# S32R372 register map
Vendor: Freescale Semiconductor, Inc.; Series: Qorivva; File version: 1.6
Registers are 32-bit, read-write, reset 0x0 unless marked. A register's access mark holds for its fields unless they carry their own. Offsets are from the block's base; [hi:lo] are bit positions; {n}, {i} and the like mark numbered series; 'fields as' and 'values as' point back to an identical list.

## CTE — CTE Memory Map
Base 0xFFD0C000; register names take the prefix CTE_
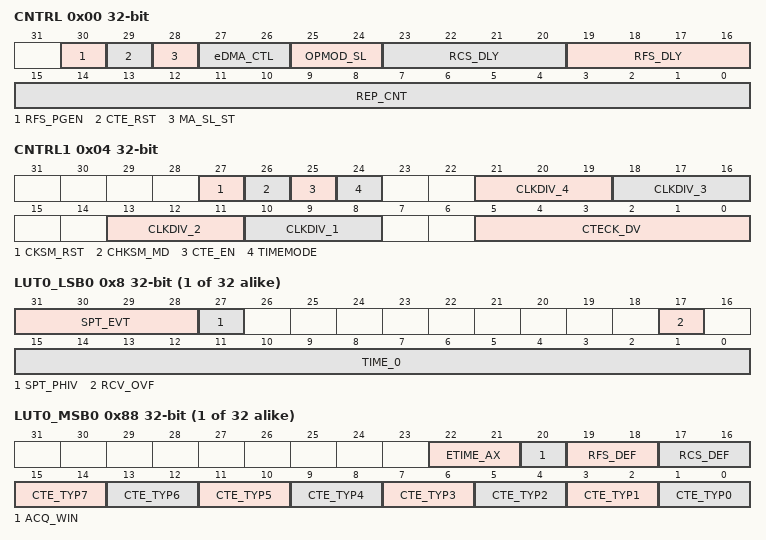
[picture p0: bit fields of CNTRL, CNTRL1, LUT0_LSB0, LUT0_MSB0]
0x00 CNTRL — Control Register
  [30] RFS_PGEN — Internal SW RFS Pulse Trigger. This bit is to be used in Slave mode only.
  [29] CTE_RST — CTE synchronous Reset
    0=CTE module reset is de-asserted; 1=CTE module reset is asserted
  [28] MA_SL_ST — master/slave select
    0=CTE is in master mode (default mode); 1=CTE is in slave mode
  [27:26] eDMA_CTL — eDMA trigger control
    0=eDMA trigger generation disabled; 1=eDMA trigger will be generated at the start of timing table; 2=eDMA trigger will be generated at the end of timing table; 3=Not used. eDMA trigger generation is disabled.
  [25:24] OPMOD_SL — CTE FSM operation mode select.
    0=Halt Mode. In this mode timing generation is stopped.; 2=Continuous run mode, Single table. In this mode the timing table is executed for the number of times programmed in the "lut_rep_cnt".; 3=Continuous toggle mode, 2 tables. In this mode, the timing tables are toggled for the number of times programmed in the "lut_rep_cnt".; 1=Continuous run mode, TT1. In this mode the second timing table (TT1) is executed for the number of times programmed in the "lut_rep_cnt".
  [23:20] RCS_DLY — Radar Chirp Synchronization Delay Control
    0=No Delay; {v}={v} clock cycle delay needs to be introduced (v=1..15)
  [19:16] RFS_DLY — Radar Frame Synchronization Delay Control
    values as RCS_DLY
  [15:0] REP_CNT — Timing Table Repetition Counter
0x04 CNTRL1 — CTE Control Register 1
  [27] CKSM_RST — Checksum Reset
    0=De-asserted. Checksum calculation functions normally.; 1=Checksum calculator block will be held in reset from next cycle onwards
  [26] CHKSM_MD — Checksum Mode
    0=Checksum mode means that the carry on the MSB is dropped (default); 1=MISR mode means that the carry on the MSB is fed back to the LSB of the checksum
  [25] CTE_EN — CTE Enable
    0=CTE is disabled. When this bit is 0, all the pending interrupts, eDMA request will be de-asserted immediately. Operational mode FSM will come to HALT and all the timing signals will be de-asserted. Internal time counter will be reset and the timing table entry counter will point to the 1st location of TT0 and all the interrupt status bits will be cleared.; 1=Timing table execution is enabled. Note that when CTE enable bit is set from 0 to 1 in the middle of operation, the timing table execution will start from address 0.
  [24] TIMEMODE — Time mode type
    0=Relative, internal time counter will reset once it reaches the current timing entry so that the next timing instance becomes relative to the current time instance; 1=Absolute, internal time counter will not be reset hence the signal states are driven at absolute timing instances
  [21:19] CLKDIV_4 — 4th Clock divider
    0=Forth clock divider's frequency is equal to CTE clock frequency; 1=Forth clock divider's frequency is equal to half the CTE clock frequency; 7=Forth clock divider's frequency is equal to 1/128 of CTE clock frequency
  [18:16] CLKDIV_3 — 3rd Clock divider
    0=Third clock divider's frequency is equal to CTE clock frequency; 1=Third clock divider's frequency is equal to half the CTE clock frequency; 7=Third clock divider's frequency is equal to 1/128 of CTE clock frequency
  [13:11] CLKDIV_2 — 2nd Clock divider
    0=Second clock divider's frequency is equal to CTE clock frequency; 1=Second clock divider's frequency is equal to half of the CTE clock frequency; 7=Second clock divider's frequency is equal to 1/128 of CTE clock frequency
  [10:8] CLKDIV_1 — 1st Clock divider
    0=First clock divider's frequency is equal to CTE clock frequency; 1=First clock divider's frequency is equal to half the CTE clock frequency; 7=First clock divider's frequency is equal to 1/128 of the CTE clock frequency
  [5:0] CTECK_DV — CTE Clock divider
    2=Datapath is operating at half the CTE clock frequency; 3=Datapath is operating at 1/3 of CTE clock frequency; 63=Datapath is operating at 1/63 of CTE clock frequency
{0x8+4i} LUT0_LSB{i} (i=0..31) — First Timing Table Register (LSB)
  [31:28] SPT_EVT — SPT Event
  [27] SPT_PHIV — SPT phase invert.
    0=Normal SPT processing requested; 1=SPT should invert the phase of the sample before processing
  [17] RCV_OVF — Receiver Overflow Mask
    0=Receiver overflow event is masked and counter is disabled; 1=Receiver overflow event is not masked and counter is enabled
  [15:0] TIME_0 — Time instance
{0x88+4i} LUT0_MSB{i} (i=0..31) — First Timing Table Register (MSB)
  [22:21] ETIME_AX — ETimer Auxiliary
    0=Both the eTimer_AUX_0 and eTimer_AUX_1 are DISABLED; 1=eTimer_AUX_0 is ENABLED and eTimer_AUX_1 is DISABLED; 2=eTimer_AUX_0 is DISABLED and eTimer_AUX_1 is ENABLED; 3=Both the eTimer_AUX_0 and eTimer_AUX_1 are ENABLED
  [20] ACQ_WIN — CTE Acquisition Window
    0=Acquisition process in SPT has not started; 1=Acquisition process in SPT has started
  [19:18] RFS_DEF — RFS definition
  [17:16] RCS_DEF — RCS definition
  [2n+1:2n] CTE_TYP{n} (n=1..7) — CTE Pulses
  [1:0] CTE_TYP0 — CTE Pulses
    0=ctep0 signal will be driven with '0' irrespective of the signal type; 1=ctep0 signal will be driven with '1' in case of logic type and toggle type. In case of clock type, divided clock with a synchronous rising edge will be sent. See CNTRL1 for divided clock description.; 2=ctep0 signal will be driven with 'Z' in case of signal type is logic. ctep0 will toggle its value toggle in case of signal type is toggle. Free running clock output of one of the 4 clock dividers will be sent on ctep0 if the type is defined as clock.; 3=No change in the signal level in case of signal type is logic and toggle. ctep0 signal will be driven with '1' in case of signal type is clock.
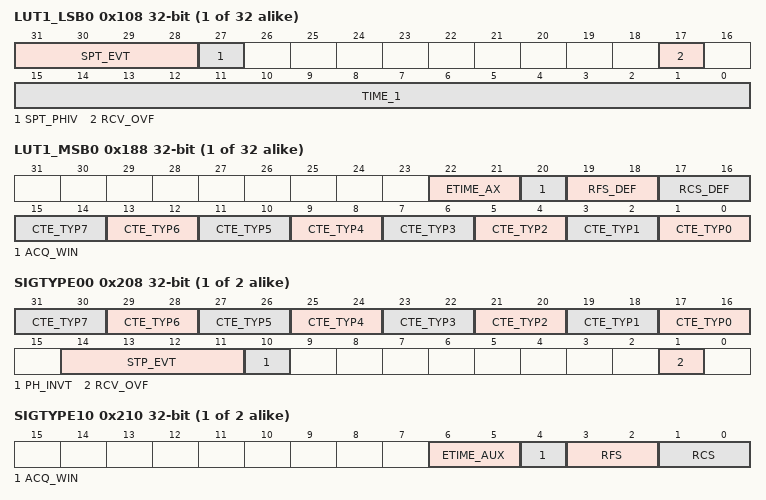
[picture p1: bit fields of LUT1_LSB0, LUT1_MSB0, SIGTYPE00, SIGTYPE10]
{0x108+4i} LUT1_LSB{i} (i=0..31) — Second Timing Table Register (LSB)
  [31:28] SPT_EVT — SPT Event
  [27] SPT_PHIV — SPT phase invert.
    values as LUT0_LSB0.SPT_PHIV
  [17] RCV_OVF — Receiver Overflow Mask
    0=Receiver overflow event is not masked and counter is enabled; 1=Receiver overflow event is masked and counter is disabled
  [15:0] TIME_1 — Time instance
{0x188+4i} LUT1_MSB{i} (i=0..31) — Second Timing Table Register (MSB)
  [22:21] ETIME_AX — ETimer Auxiliary
    values as LUT0_MSB0.ETIME_AX
  [20] ACQ_WIN — CTE Acquisition Window
    values as LUT0_MSB0.ACQ_WIN
  [19:18] RFS_DEF — RFS definition
  [17:16] RCS_DEF — RCS definition
  [2n+1:2n] CTE_TYP{n} (n=0..7) — CTE Pulses
{0x208+4i} SIGTYPE0{i} (i=0..1) — Signal Type Register 0
  [2n+17:2n+16] CTE_TYP{n} (n=0..7) — CTE pulse type
    0=Signal state will be 'Z'; 1=Signal type is Toggle; 2=Signal type is Clock; 3=Signal type is Logic
  [14:11] STP_EVT — SPT event type
    0=Signal type is logic; 1=Signal type is pulse
  [10] PH_INVT — Phase invert type
    0=Signal type is logic; 1=Signal type is pulse
  [1] RCV_OVF — Receive overflow mask type
    0=Signal type is logic; 1=Signal type is pulse
{0x210+4i} SIGTYPE1{i} (i=0..1) — Signal Type Register 1
  [6:5] ETIME_AUX — Etime Aux Type
    0=Signal Type of eTimer_AUX_0 and eTimer_AUX_1 are Logic; 1=Signal Type of eTimer_AUX_0 is Pulse and eTimer_AUX_1 is Logic; 2=Signal Type of eTimer_AUX_0 is Logic and eTimer_AUX_1 is Pulse; 3=Signal Type of eTimer_AUX_0 and eTimer_AUX_1 are Pulse
  [4] ACQ_WIN — Acquisition Window Type
    0=Signal type is logic; 1=Signal type is pulse
  [3:2] RFS — Radar Frame Synchronization
    values as SIGTYPE00.CTE_TYP0
  [1:0] RCS — Radar Chirp Synchronization
    values as SIGTYPE00.CTE_TYP0
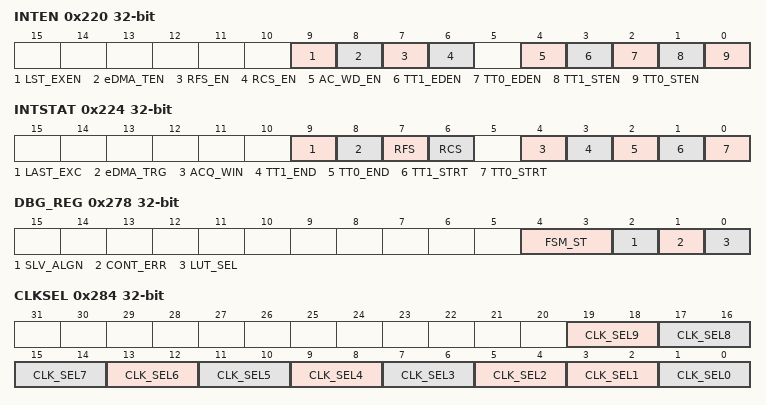
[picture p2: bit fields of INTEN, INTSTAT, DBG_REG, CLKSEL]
0x220 INTEN — CTE Interrupt Enable Register
  [9] LST_EXEN — Last Table Execution Enable
    0=Disabled; 1=An interrupt will be generated when the execution of the timing table is finished for the final time as configured
  [8] eDMA_TEN — eDMA Trigger Interrupt Enable
    0=Disabled; 1=An interrupt will be generated on the rising edge of the eDMA trigger
  [7] RFS_EN — RFS interrupt enable (rising edge)
    0=Disabled; 1=An interrupt will be generated on the rising edge of the RFS
  [6] RCS_EN — RCS interrupt enable (rising edge)
    0=Disabled; 1=An interrupt will be generated on the rising edge of the RCS
  [4] AC_WD_EN — Acquisition window (rising)
    0=Disabled; 1=An interrupt will be generated on the rising edge of the acquisition window signal
  [3] TT1_EDEN — Timing table end (rising)
    0=Disabled; 1=An interrupt will be generated on the rising edge of the second timing table end signal
  [2] TT0_EDEN — Timing table end (rising)
    0=Disabled; 1=An interrupt will be generated on the rising edge of the first timing table end signal
  [1] TT1_STEN — Timing table start (rising)
    0=Disabled; 1=An interrupt will be generated on the rising edge of the second timing table start signal
  [0] TT0_STEN — Timing table start (rising)
    0=Disabled; 1=An interrupt will be generated on the rising edge of the first timing table start signal
0x224 INTSTAT — CTE Interrupt Status Register
  [9] LAST_EXC — Last Execution
  [8] eDMA_TRG — eDMA Trigger
  [7] RFS — Radar Frame Synchronization
  [6] RCS — Radar Chirp Synchronization
  [4] ACQ_WIN — Acquisition window (rising)
  [3] TT1_END
  [2] TT0_END
  [1] TT1_STRT — TT1 start
  [0] TT0_STRT — TT0 start
0x22C RCVOFCNT ro — Receiver Overflow Counter
  [31:0] RCV_OVCT — Receiver Overflow counter
0x270 CKSM_LSB — LUT Checksum Register
  [31:0] CHKS_LSB — Checksum Result LSB
0x274 CKSM_MSB — LUT Checksum Register
  [7:0] CHKS_MSB — Checksum Result LSB
0x278 DBG_REG — Debug Register
  [4:3] FSM_ST ro — OPMOD FSM state
    0=FSM is in HALT; 1=FSM is in CRUN Table 0; 2=FSM is in CRUN Table 1
  [2] SLV_ALGN — RFS/RCS align status
    0=RFS and RCS input are not aligned; 1=RFS and RCS input are aligned
  [1] CONT_ERR — Timing Table contention error
    0=No timing table contention has occurred; 1=Contention has occurred on the active timing table
  [0] LUT_SEL ro — TT Select
    0=TT0 is currently being used for signal definitions; 1=TT1 is currently being used for signal definitions
0x27C LUT_DUR — TT0 Execution Duration Register
  [31:0] TT0_DUR — TT0 Duration
0x280 LUT_DUR1 — TT1 Execution Duration Register
  [31:0] TT1_DUR — TT1_DURATION
0x284 CLKSEL — Clock Select Register
  [19:18] CLK_SEL9 — Clock Select
    0=1st clock divider will be used for generating the clock type signal on RFS; 1=2nd clock divider will be used for generating the clock type signal on RFS; 2=3rd clock divider will be used for generating the clock type signal on RFS; 3=4th clock divider will be used for generating the clock type signal on RFS
  [17:16] CLK_SEL8 — Clock Select
    0=1st clock divider will be used for generating the clock type signal on RCS; 1=2nd clock divider will be used for generating the clock type signal on RCS; 2=3rd clock divider will be used for generating the clock type signal on RCS; 3=4th clock divider will be used for generating the clock type signal on RCS
  [2n+1:2n] CLK_SEL{n} (n=2..7) — Clock Select
    0=1st clock divider will be used for generating the clock type signal on ctep{n}; 1=2nd clock divider will be used for generating the clock type signal on ctep{n}; 2=3rd clock divider will be used for generating the clock type signal on ctep{n}; 3=4th clock divider will be used for generating the clock type signal on ctep{n}
  [3:2] CLK_SEL1 — Clock Select. These bits are used to select one of the 4 available clock dividers for ctep1 when it is defined as clock type.
    0=1st clock divider will be used for generating the clock type signal on ctep1; 1=2nd clock divider will be used for generating the clock type signal on ctep1; 2=3rd clock divider will be used for generating the clock type signal on ctep1; 3=4th clock divider will be used for generating the clock type signal on ctep1
  [1:0] CLK_SEL0 — Clock Select
    0=1st clock divider will be used for generating the clock type signal on ctep0; 1=2nd clock divider will be used for generating the clock type signal on ctep0; 2=3rd clock divider will be used for generating the clock type signal on ctep0; 3=4th clock divider will be used for generating the clock type signal on ctep0
